# f28002x_erad_counter_regs register map
Vendor: Texas Instruments
Peripheral module from a debugger description file (folder C2000).
Address unit: 16 bits
Registers are 16-bit, read-write, no defined reset value unless marked. A register's access mark holds for its fields unless they carry their own. Offsets are as the file gives them; lines under a group give offsets from that group; [hi:lo] are bit positions; {n}, {i} and the like mark numbered series; 'fields as' and 'values as' point back to an identical list; <NAME> marks a mode.

## ERAD_COUNTER_REGS — ERAD COUNTER Registers
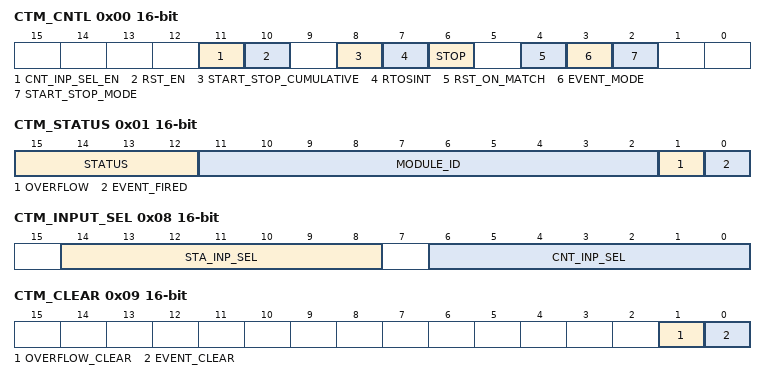
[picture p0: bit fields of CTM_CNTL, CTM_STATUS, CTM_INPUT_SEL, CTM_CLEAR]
0x00 CTM_CNTL — Counter Control Register
  [11] CNT_INP_SEL_EN — Counter Input Select Enable
  [10] RST_EN — Enable Reset
  [8] START_STOP_CUMULATIVE — Start stop cumulative bit
  [7] RTOSINT — RTOSINT bit
  [6] STOP — Stop bit (Halt/No Halt of CPU)
  [4] RST_ON_MATCH — Reset_on_match bit
  [3] EVENT_MODE — Event mode bit
  [2] START_STOP_MODE — Start_stop mode bit
0x01 CTM_STATUS ro — Counter Status Register
  [15:12] STATUS — Status bits
  [11:2] MODULE_ID — Identification bits
  [1] OVERFLOW — Counter Overflowed
  [0] EVENT_FIRED — Counter Event Fired bits
0x02 CTM_REF 32-bit — Counter Reference Register
  [31:0] REF — The counter reference register
0x04 CTM_COUNT 32-bit — Counter Current Value Register
  [31:0] COUNT — The counter value register
0x06 CTM_MAX_COUNT 32-bit — Counter Max Count Value Register
  [31:0] MAX_COUNT — The maximum recorded counter value.
0x08 CTM_INPUT_SEL — Counter Input Select Register
  [14:8] STA_INP_SEL — Counter Sart Input Select
  [6:0] CNT_INP_SEL — Counter Input Select
0x09 CTM_CLEAR — Counter Clear Register
  [1] OVERFLOW_CLEAR — Clear OVERFLOW
  [0] EVENT_CLEAR — Clear EVENT_FIRED
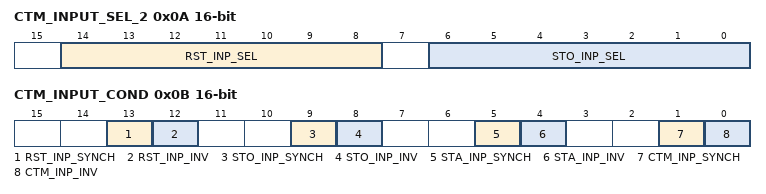
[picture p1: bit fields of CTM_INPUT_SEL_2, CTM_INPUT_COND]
0x0A CTM_INPUT_SEL_2 — Counter Input Select Extension Register
  [14:8] RST_INP_SEL — Counter Reset input Select
  [6:0] STO_INP_SEL — Counter Stop Input Select
0x0B CTM_INPUT_COND — Counter Input Conditioning Register
  [13] RST_INP_SYNCH — Reset input synchronizer enable
  [12] RST_INP_INV — Reset input Invert
  [9] STO_INP_SYNCH — Stop input synchronizer enable
  [8] STO_INP_INV — Stop input Invert
  [5] STA_INP_SYNCH — Start input synchronizer enable
  [4] STA_INP_INV — Start input Invert
  [1] CTM_INP_SYNCH — Counter input synchronizer enable
  [0] CTM_INP_INV — Counter Input Invert
